# N32H7xx register map
Vendor: Nationstech Ltd.; File version: 1.0
CPU: CM7 r1p1, little endian, MPU, FPU, 4 interrupt priority bits
Registers are 32-bit, read-write, reset 0x0 unless marked. A register's access mark holds for its fields unless they carry their own. Offsets are from the block's base; [hi:lo] are bit positions; {n}, {i} and the like mark numbered series; 'fields as' and 'values as' point back to an identical list.

## DEC — peripherals to Host
Base 0x50080000
0x00 JPEGDEC_MODE — Mode
  [0] EN
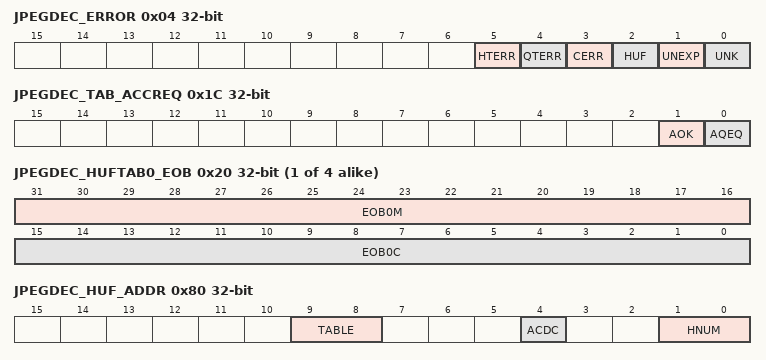
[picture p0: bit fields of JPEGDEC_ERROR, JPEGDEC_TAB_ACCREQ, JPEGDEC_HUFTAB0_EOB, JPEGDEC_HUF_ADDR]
0x04 JPEGDEC_ERROR — Error register
  [5] HTERR, [4] QTERR, [3] CERR, [2] HUF, [1] UNEXP, [0] UNK
0x08 JPEGDEC_UNLOC ro — Unknown marker error location (write 0 to clear, write 1 keeps current value)
  [31:0] POS
0x0C JPEGDEC_UELOC ro — In the event of an unexpected marker error, the decoder stores the location of the unexpected marker in this register. The location is the byte-offset from the last SOI marker processed.
  [31:0] POS
0x10 JPEGDEC_HESYM ro — Huffman error symbol
  [15:0] HESYM
0x14 JPEGDEC_HESYMECS ro — ECS number of Huffman symbol error
  [31:0] NUM
0x18 JPEGDEC_HUF_SELOC ro — Huffman symbol error location in ECS
  [31:0] POS
0x1C JPEGDEC_TAB_ACCREQ — Table access request
  [1] AOK ro, [0] AQEQ
{0x20+4i} JPEGDEC_HUFTAB{i}_EOB (i=0..3) — Huffman table {i} EOB symbol
  [31:16] EOB{i}M, [15:0] EOB{i}C
0x80 JPEGDEC_HUF_ADDR — Huffman table access address
  [9:8] TABLE, [4] ACDC, [1:0] HNUM
0x84 JPEGDEC_HUF_DATA — Huffman table access data
  [31:0] HDATA
0x88 JPEGDEC_HUF_REM — Huffman table access number of words remaining from the currently selected Huffman table
  [31:0] HREM
{0x400+4i} JPEGDEC_QT0_{i} (i=0..63) — JPEGDEC_QT0_{i}
  [7:0] QT0
{0x500+4i} JPEGDEC_QT1_{i} (i=0..63) — JPEGDEC_QT1_{i}
  [7:0] QT1
{0x600+4i} JPEGDEC_QT2_{i} (i=0..63) — JPEGDEC_QT2_{i}
  [7:0] QT2
{0x700+4i} JPEGDEC_QT3_{i} (i=0..63) — JPEGDEC_QT3_{i}
  [7:0] QT3

## DBG — Debug
Base 0x58035400
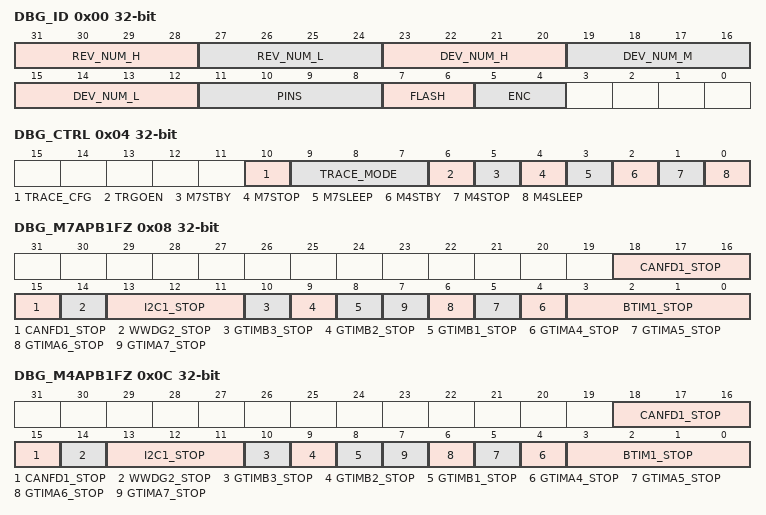
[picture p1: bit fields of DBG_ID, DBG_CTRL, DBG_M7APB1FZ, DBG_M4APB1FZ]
0x00 DBG_ID ro — DBGMCU Identity code register
  [31:28] REV_NUM_H
  [27:24] REV_NUM_L
  [23:20] DEV_NUM_H
  [19:16] DEV_NUM_M
  [15:12] DEV_NUM_L
  [11:8] PINS
  [7:6] FLASH — FLASH capacity
  [5:4] ENC
0x04 DBG_CTRL — Control Register
  [10] TRACE_CFG, [9:7] TRACE_MODE, [6] TRGOEN, [5] M7STBY, [4] M7STOP, [3] M7SLEEP, [2] M4STBY, [1] M4STOP, [0] M4SLEEP
0x08 DBG_M7APB1FZ — DBGMCU APB1 peripheral freeze register CPU1
  [18:15] CANFD1_STOP, [14] WWDG2_STOP, [13:11] I2C1_STOP, [10] GTIMB3_STOP, [9] GTIMB2_STOP, [8] GTIMB1_STOP, [n] GTIMA{n}_STOP (n=4..7), [3:0] BTIM1_STOP
0x0C DBG_M4APB1FZ — DBGMCU APB1 peripheral freeze register CPU2
  fields as DBG_M7APB1FZ
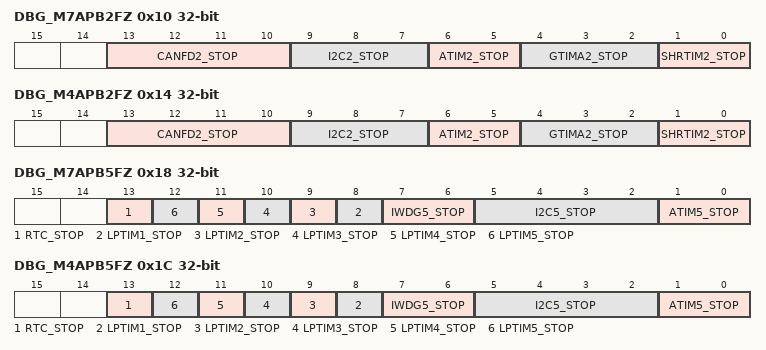
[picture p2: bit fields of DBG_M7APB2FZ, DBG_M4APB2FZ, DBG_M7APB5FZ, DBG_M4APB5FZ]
0x10 DBG_M7APB2FZ — DBGMCU APB2 peripheral freeze register CPU1
  [13:10] CANFD2_STOP, [9:7] I2C2_STOP, [6:5] ATIM2_STOP, [4:2] GTIMA2_STOP, [1:0] SHRTIM2_STOP
0x14 DBG_M4APB2FZ — DBGMCU APB2 peripheral freeze register CPU2
  fields as DBG_M7APB2FZ
0x18 DBG_M7APB5FZ — DBGMCU APB5 peripheral freeze register CPU1
  [13] RTC_STOP, [n+7] LPTIM{n}_STOP (n=1..5), [7:6] IWDG5_STOP, [5:2] I2C5_STOP, [1:0] ATIM5_STOP
0x1C DBG_M4APB5FZ — DBGMCU APB5 peripheral freeze register CPU2
  fields as DBG_M7APB5FZ
0x20 DBG_M7APB6FZ — DBGMCU APB6 peripheral freeze register CPU1
  [0] WWDG1_STOP
0x24 DBG_M4APB6FZ — DBGMCU APB6 peripheral freeze register CPU2
  [0] WWDG1_STOP

## DVP1 — Digital video port
Base 0x50048000
Same registers: DVP2 0x50049000
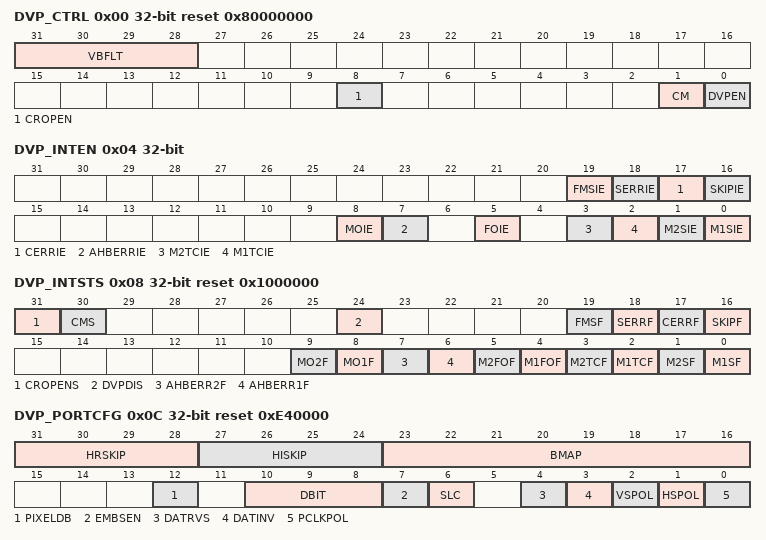
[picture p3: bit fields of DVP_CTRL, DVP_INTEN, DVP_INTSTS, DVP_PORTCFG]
0x00 DVP_CTRL reset 0x80000000
  [31:28] VBFLT, [8] CROPEN, [1] CM, [0] DVPEN
0x04 DVP_INTEN
  [19] FMSIE, [18] SERRIE, [17] CERRIE, [16] SKIPIE, [8] MOIE, [7] AHBERRIE, [5] FOIE, [3] M2TCIE, [2] M1TCIE, [1] M2SIE, [0] M1SIE
0x08 DVP_INTSTS reset 0x1000000
  [31] CROPENS ro
  [30] CMS ro
  [24] DVPDIS
  [19] FMSF write-1-clears
  [18] SERRF write-1-clears
  [17] CERRF write-1-clears
  [16] SKIPF write-1-clears
  [9] MO2F write-1-clears — M2OF
  [8] MO1F write-1-clears — M1OF
  [7] AHBERR2F write-1-clears
  [6] AHBERR1F write-1-clears
  [5] M2FOF write-1-clears
  [4] M1FOF write-1-clears
  [3] M2TCF write-1-clears
  [2] M1TCF write-1-clears
  [1] M2SF write-1-clears
  [0] M1SF write-1-clears
0x0C DVP_PORTCFG reset 0xE40000
  [31:28] HRSKIP, [27:24] HISKIP, [23:16] BMAP, [12] PIXELDB, [10:8] DBIT, [7] EMBSEN, [6] SLC, [4] DATRVS, [3] DATINV, [2] VSPOL, [1] HSPOL, [0] PCLKPOL
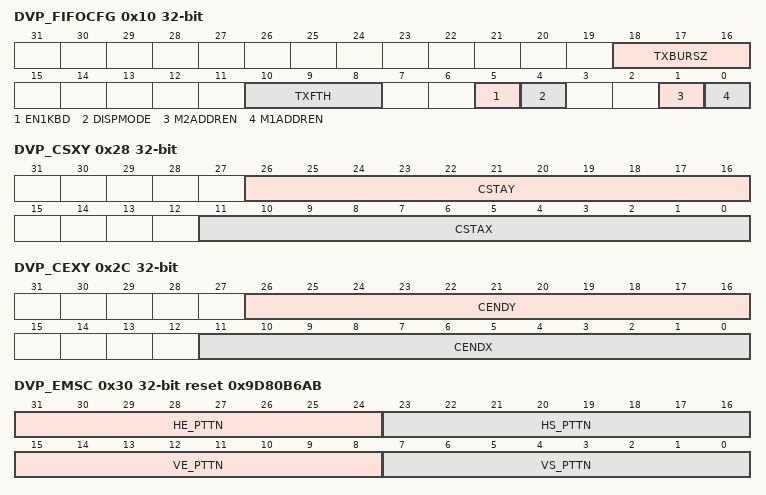
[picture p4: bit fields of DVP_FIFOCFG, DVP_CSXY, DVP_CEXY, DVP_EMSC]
0x10 DVP_FIFOCFG
  [18:16] TXBURSZ, [10:8] TXFTH, [5] EN1KBD, [4] DISPMODE, [1] M2ADDREN, [0] M1ADDREN
0x14 DVP_SMADDR1
  [31:0] MADDR
0x18 DVP_SMADDR2
  [31:0] MADDR
0x1C DVP_FBS
  [21:0] FMSIZE
0x20 DVP_FPBC1 ro
  [31:0] PIXLC
0x24 DVP_FPBC2 ro
  [31:0] PIXLC
0x28 DVP_CSXY
  [26:16] CSTAY, [11:0] CSTAX
0x2C DVP_CEXY
  [26:16] CENDY, [11:0] CENDX
0x30 DVP_EMSC reset 0x9D80B6AB
  [31:24] HE_PTTN, [23:16] HS_PTTN, [15:8] VE_PTTN, [7:0] VS_PTTN
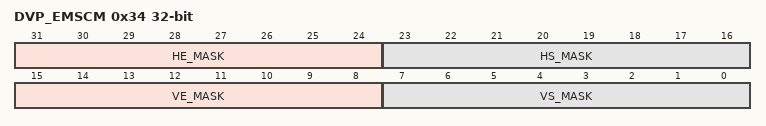
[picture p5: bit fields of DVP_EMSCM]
0x34 DVP_EMSCM
  [31:24] HE_MASK, [23:16] HS_MASK, [15:8] VE_MASK, [7:0] VS_MASK
